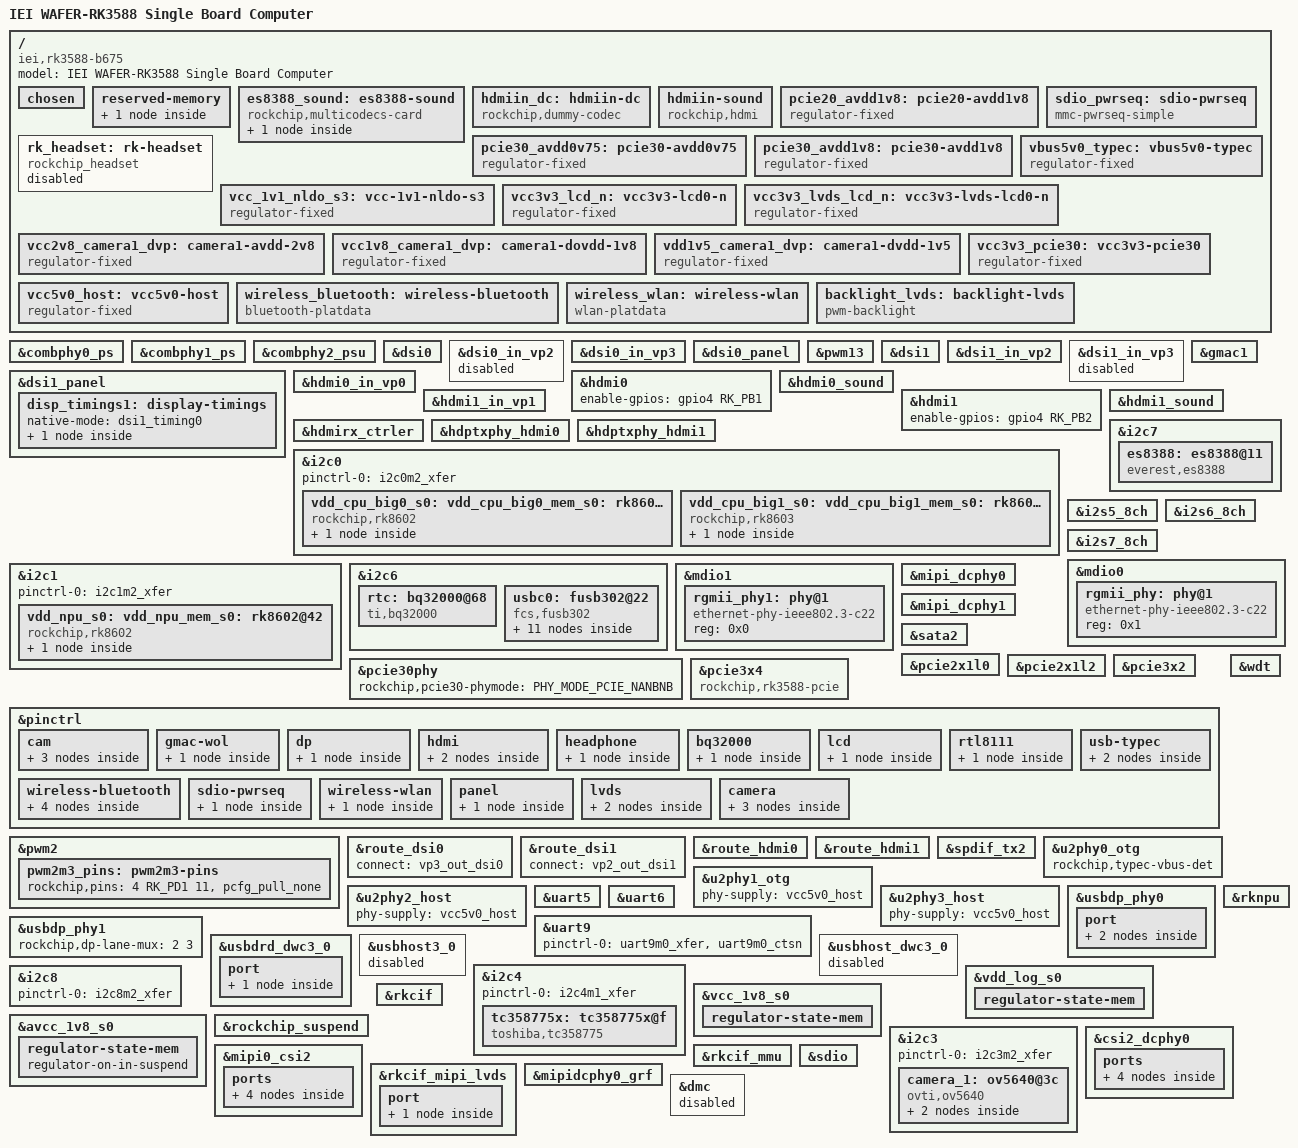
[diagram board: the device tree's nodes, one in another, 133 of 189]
// SPDX-License-Identifier: (GPL-2.0+ OR MIT)
/*
 * Copyright (c) 2024 IEI World Co., Ltd.
 * Author: LC Wang <lcwang@ieiworld.com>
 *
 */

/dts-v1/;

#include "dt-bindings/usb/pd.h"
#include "rk3588.dtsi"
#include "rk3588-evb.dtsi"
#include "rk3588-rk806-single.dtsi"
#include "rk3588-android.dtsi"

/ {

	model = "IEI WAFER-RK3588 Single Board Computer";
	compatible = "iei,rk3588-b675", "rockchip,rk3588";

	chosen: chosen {
		bootargs = "earlycon=uart8250,mmio32,0xfeb50000 console=ttyFIQ0 irqchip.gicv3_pseudo_nmi=0 rcupdate.rcu_expedited=1 rcu_nocbs=all quiet";
	};

	/* If hdmirx node is disabled, delete the reserved-memory node here. */
	reserved-memory {
		#address-cells = <2>;
		#size-cells = <2>;
		ranges;

		/* Reserve 128MB memory for hdmirx-controller@fdee0000 */
		cma {
			compatible = "shared-dma-pool";
			reusable;
			reg = <0x0 (256 * 0x100000) 0x0 (128 * 0x100000)>;
			linux,cma-default;
		};
	};

	es8388_sound: es8388-sound {
		status = "okay";
		compatible = "rockchip,multicodecs-card";
		rockchip,card-name = "rockchip-es8388";
		hp-det-gpio = <&gpio1 RK_PC4 GPIO_ACTIVE_LOW>;
		io-channels = <&saradc 3>;
		io-channel-names = "adc-detect";
		keyup-threshold-microvolt = <1800000>;
		poll-interval = <100>;
		rockchip,format = "i2s";
		rockchip,mclk-fs = <256>;
		rockchip,cpu = <&i2s0_8ch>;
		rockchip,codec = <&es8388>;
		rockchip,audio-routing =
			"Headphone", "LOUT1",
			"Headphone", "ROUT1",
			"Speaker", "LOUT2",
			"Speaker", "ROUT2",
			"Headphone", "Headphone Power",
			"Headphone", "Headphone Power",
			"Speaker", "Speaker Power",
			"Speaker", "Speaker Power",
			"LINPUT1", "Main Mic",
			"LINPUT2", "Main Mic",
			"RINPUT1", "Headset Mic",
			"RINPUT2", "Headset Mic";
		pinctrl-names = "default";
		pinctrl-0 = <&hp_det>;
		play-pause-key {
			label = "playpause";
			linux,code = <KEY_PLAYPAUSE>;
			press-threshold-microvolt = <2000>;
		};
	};

	hdmiin_dc: hdmiin-dc {
		compatible = "rockchip,dummy-codec";
		#sound-dai-cells = <0>;
		status = "okay";
	};

	hdmiin-sound {
		compatible = "rockchip,hdmi";
		rockchip,mclk-fs = <128>;
		rockchip,format = "i2s";
		rockchip,bitclock-master = <&hdmirx_ctrler>;
		rockchip,frame-master = <&hdmirx_ctrler>;
		rockchip,card-name = "rockchip,hdmiin";
		rockchip,cpu = <&i2s7_8ch>;
		rockchip,codec = <&hdmirx_ctrler 0>;
		rockchip,jack-det;
	};

	pcie20_avdd1v8: pcie20-avdd1v8 {
		compatible = "regulator-fixed";
		regulator-name = "pcie20_avdd1v8";
		regulator-boot-on;
		regulator-always-on;
		regulator-min-microvolt = <1800000>;
		regulator-max-microvolt = <1800000>;
		vin-supply = <&avcc_1v8_s0>;
	};

	pcie30_avdd0v75: pcie30-avdd0v75 {
		compatible = "regulator-fixed";
		regulator-name = "pcie30_avdd0v75";
		regulator-boot-on;
		regulator-always-on;
		regulator-min-microvolt = <750000>;
		regulator-max-microvolt = <750000>;
		vin-supply = <&avdd_0v75_s0>;
	};

	pcie30_avdd1v8: pcie30-avdd1v8 {
		compatible = "regulator-fixed";
		regulator-name = "pcie30_avdd1v8";
		regulator-boot-on;
		regulator-always-on;
		regulator-min-microvolt = <1800000>;
		regulator-max-microvolt = <1800000>;
		vin-supply = <&avcc_1v8_s0>;
	};


	sdio_pwrseq: sdio-pwrseq {
		compatible = "mmc-pwrseq-simple";
		pinctrl-names = "default";
		pinctrl-0 = <&wifi_enable_h>;
		reset-gpios = <&gpio0 RK_PA4 GPIO_ACTIVE_LOW>;
	};

	rk_headset: rk-headset {
		status = "disabled";
		compatible = "rockchip_headset";
		headset_gpio = <&gpio1 RK_PC4 GPIO_ACTIVE_LOW>;
		pinctrl-names = "default";
		pinctrl-0 = <&hp_det>;
		io-channels = <&saradc 3>;
	};

	vbus5v0_typec: vbus5v0-typec {
		compatible = "regulator-fixed";
		regulator-name = "vbus5v0_typec";
		regulator-min-microvolt = <5000000>;
		regulator-max-microvolt = <5000000>;
		enable-active-high;
		gpio = <&gpio4 RK_PA1 GPIO_ACTIVE_HIGH>;
		vin-supply = <&vcc5v0_usb>;
		pinctrl-names = "default";
		pinctrl-0 = <&typec5v_pwren>;
	};

	vcc_1v1_nldo_s3: vcc-1v1-nldo-s3 {
		compatible = "regulator-fixed";
		regulator-name = "vcc_1v1_nldo_s3";
		regulator-always-on;
		regulator-boot-on;
		regulator-min-microvolt = <1100000>;
		regulator-max-microvolt = <1100000>;
		vin-supply = <&vcc5v0_sys>;
	};

	vcc3v3_lcd_n: vcc3v3-lcd0-n {
		compatible = "regulator-fixed";
		regulator-name = "vcc3v3_lcd0_n";
		regulator-always-on;
		regulator-boot-on;
		enable-active-high;
		gpio = <&gpio3 RK_PA6 GPIO_ACTIVE_HIGH>;
		pinctrl-names = "default";
		pinctrl-0 = <&panel_en>;
		regulator-min-microvolt = <3300000>;
		regulator-max-microvolt = <3300000>;

	};

	vcc3v3_lvds_lcd_n: vcc3v3-lvds-lcd0-n {
		compatible = "regulator-fixed";
		regulator-name = "vcc3v3_lvds_lcd0_n";
		regulator-always-on;
		regulator-boot-on;
		enable-active-high;
		gpio = <&gpio2 RK_PC1 GPIO_ACTIVE_HIGH>;
		pinctrl-names = "default";
		pinctrl-0 = <&lvds_lcd_en>;
		regulator-min-microvolt = <3300000>;
		regulator-max-microvolt = <3300000>;
	};

	vcc2v8_camera1_dvp: camera1-avdd-2v8 {
		compatible = "regulator-fixed";
		regulator-name = "camera1_avdd";
		regulator-min-microvolt = <2800000>;
		regulator-max-microvolt = <2800000>;
		regulator-always-on;
		regulator-boot-on;
		enable-active-high;
	};

	vcc1v8_camera1_dvp: camera1-dovdd-1v8 {
		compatible = "regulator-fixed";
		regulator-name = "camera1_dovdd";
		regulator-min-microvolt = <1800000>;
		regulator-max-microvolt = <1800000>;
		regulator-always-on;
		regulator-boot-on;
		enable-active-high;
	};

	vdd1v5_camera1_dvp: camera1-dvdd-1v5 {
		compatible = "regulator-fixed";
		regulator-name = "camera1_dvdd";
		regulator-min-microvolt = <1500000>;
		regulator-max-microvolt = <1500000>;
		regulator-always-on;
		regulator-boot-on;
		enable-active-high;
	};

	vcc3v3_pcie30: vcc3v3-pcie30 {
		compatible = "regulator-fixed";
		regulator-name = "vcc3v3_pcie30";
		regulator-min-microvolt = <3300000>;
		regulator-max-microvolt = <3300000>;
		enable-active-high;
		gpios = <&gpio2 RK_PC5 GPIO_ACTIVE_HIGH>;
		startup-delay-us = <5000>;
		vin-supply = <&vcc12v_dcin>;
	};

	vcc5v0_host: vcc5v0-host {
		compatible = "regulator-fixed";
		regulator-name = "vcc5v0_host";
		regulator-boot-on;
		regulator-always-on;
		regulator-min-microvolt = <5000000>;
		regulator-max-microvolt = <5000000>;
		enable-active-high;
		vin-supply = <&vcc5v0_usb>;
		pinctrl-names = "default";
	};

	wireless_bluetooth: wireless-bluetooth {
		compatible = "bluetooth-platdata";
		uart_rts_gpios = <&gpio4 RK_PC4 GPIO_ACTIVE_LOW>;
		pinctrl-names = "default", "rts_gpio";
		pinctrl-0 = <&uart9m0_rtsn>, <&bt_reset_gpio>, <&bt_wake_gpio>, <&bt_irq_gpio>;
		pinctrl-1 = <&uart9_gpios>;
		BT,reset_gpio    = <&gpio1 RK_PB2 GPIO_ACTIVE_HIGH>;
		BT,wake_gpio     = <&gpio1 RK_PB1 GPIO_ACTIVE_HIGH>;
		BT,wake_host_irq = <&gpio0 RK_PA0 GPIO_ACTIVE_HIGH>;
		status = "okay";
	};

	wireless_wlan: wireless-wlan {
		compatible = "wlan-platdata";
		wifi_chip_type = "ap6275s";
		pinctrl-names = "default";
		pinctrl-0 = <&wifi_host_wake_irq>;
		WIFI,host_wake_irq = <&gpio0 RK_PB2 GPIO_ACTIVE_HIGH>;
		status = "okay";
	};

	backlight_lvds: backlight-lvds {
		compatible = "pwm-backlight";
		brightness-levels = <
			0   1   2   3   4   5   6   7
			8   9  10  11  12  13  14  15
			16  17  18  19  20  21  22  23
			24  25  26  27  28  29  30  31
			32  33  34  35  36  37  38  39
			40  41  42  43  44  45  46  47
			48  49  50  51  52  53  54  55
			56  57  58  59  60  61  62  63
			64  65  66  67  68  69  70  71
			72  73  74  75  76  77  78  79
			80  81  82  83  84  85  86  87
			88  89  90  91  92  93  94  95
			96  97  98  99 100 101 102 103
			104 105 106 107 108 109 110 111
			112 113 114 115 116 117 118 119
			120 121 122 123 124 125 126 127
			128 129 130 131 132 133 134 135
			136 137 138 139 140 141 142 143
			144 145 146 147 148 149 150 151
			152 153 154 155 156 157 158 159
			160 161 162 163 164 165 166 167
			168 169 170 171 172 173 174 175
			176 177 178 179 180 181 182 183
			184 185 186 187 188 189 190 191
			192 193 194 195 196 197 198 199
			200 201 202 203 204 205 206 207
			208 209 210 211 212 213 214 215
			216 217 218 219 220 221 222 223
			224 225 226 227 228 229 230 231
			232 233 234 235 236 237 238 239
			240 241 242 243 244 245 246 247
			248 249 250 251 252 253 254 255
		>;
		default-brightness-level = <200>;
		pwms = <&pwm2 0 25000 0>;
		enable-gpios = <&gpio4 RK_PD1 GPIO_ACTIVE_HIGH>;
	};
};

&combphy0_ps {
	status = "okay";
};

&combphy1_ps {
	status = "okay";
};

&combphy2_psu {
	status = "okay";
};

/*
 * mipi_dcphy0 needs to be enabled
 * when dsi0 is enabled
 */
&dsi0 {
	status = "okay";
};

&dsi0_in_vp2 {
	status = "disabled";
};

&dsi0_in_vp3 {
	status = "okay";
};

&dsi0_panel {
};

&pwm13 {
	status = "okay";
};

/*
 * mipi_dcphy1 needs to be enabled
 * when dsi1 is enabled
 */
&dsi1 {
	status = "okay";
};

&dsi1_in_vp2 {
	status = "okay";
};

&dsi1_in_vp3 {
	status = "disabled";
};

// TC358774
&dsi1_panel {
	power-supply = <&vcc3v3_lvds_lcd_n>;
	reset-gpios = <&gpio4 RK_PC2 GPIO_ACTIVE_LOW>;
	enable-delay-ms = <20>;
	prepare-delay-ms = <120>;
	unprepare-delay-ms = <120>;
	disable-delay-ms = <20>;
	/delete-property/ reset-delay-ms;
	pinctrl-names = "default";
	pinctrl-0 = <&lvds_lcd_rst>;
	backlight = <&backlight_lvds>;
	no-panel-reinit;

	panel-init-sequence = [
		// TC358774/75XBG DSI Basic Parameters.  Following 10 setting should be pefromed in LP mode
		29 00 06 3C 01 0B 00 08 00
		29 00 06 14 01 07 00 00 00
		29 00 06 64 01 0C 00 00 00
		29 00 06 68 01 0C 00 00 00
		29 00 06 6C 01 0C 00 00 00
		29 00 06 70 01 0C 00 00 00
		29 00 06 34 01 1F 00 00 00
		29 00 06 10 02 1F 00 00 00
		29 00 06 04 01 01 00 00 00
		29 00 06 04 02 01 00 00 00

		// TC358774/75XBG Timing and mode setting
		29 00 06 50 04 20 01 F0 03
		29 00 06 54 04 32 00 B4 00
		29 00 06 58 04 80 07 48 00
		29 00 06 5C 04 0C 00 18 00
		29 00 06 60 04 B0 04 18 00
		29 00 06 64 04 01 00 00 00
		29 01 06 A0 04 06 80 44 00
		29 00 06 A0 04 06 80 04 00
		29 00 06 04 05 04 00 00 00

		// TC358774/75XBG LVDS Color mapping setting
		29 00 06 80 04 00 01 02 03
		29 00 06 84 04 04 07 05 08
		29 00 06 88 04 09 0A 0E 0F
		29 00 06 8C 04 0B 0C 0D 10
		29 00 06 90 04 16 17 11 12
		29 00 06 94 04 13 14 15 1B
		29 00 06 98 04 18 19 1A 06

		// TC358774/75XBG LVDS enable
		29 00 06 9C 04 33 04 00 00
	];

	panel-exit-sequence = [
		05 05 01 28
		05 78 01 10
	];

	disp_timings1: display-timings {
		native-mode = <&dsi1_timing0>;
		dsi1_timing0: timing0 {
			clock-frequency = <168000000>;
			hactive = <1920>;
			hsync-len = <50>;
			hback-porch = <180>;
			hfront-porch = <72>;
			vactive = <1200>;
			vsync-len = <12>;
			vback-porch = <24>;
			vfront-porch = <24>;
			hsync-active = <0>;
			vsync-active = <0>;
			de-active = <0>;
			pixelclk-active = <0>;
		};
	};
};

&gmac1 {
	/* Use rgmii-rxid mode to disable rx delay inside Soc */
	phy-mode = "rgmii-rxid";
	clock_in_out = "output";
	wolirq-gpio = <&gpio4 RK_PC6 GPIO_ACTIVE_LOW>;
	snps,reset-gpio = <&gpio3 RK_PB7 GPIO_ACTIVE_LOW>;
	snps,reset-active-low;
	/* Reset time is 20ms, 100ms for rtl8211f */
	snps,reset-delays-us = <0 50000 100000>;

	pinctrl-names = "default";
	pinctrl-0 = <&gmac1_miim
		     &gmac1_tx_bus2
		     &gmac1_rx_bus2
		     &gmac1_rgmii_clk
		     &gmac1_rgmii_bus
		     &gmac1_pmeb_gpios>;

	tx_delay = <0x43>;
	/* rx_delay = <0x3f>; */

	phy-handle = <&rgmii_phy1>;
	status = "okay";
};

&hdmi0 {
	enable-gpios = <&gpio4 RK_PB1 GPIO_ACTIVE_HIGH>;
	status = "okay";
};

&hdmi0_in_vp0 {
	status = "okay";
};

&hdmi0_sound {
	status = "okay";
};

&hdmi1 {
	enable-gpios = <&gpio4 RK_PB2 GPIO_ACTIVE_HIGH>;
	status = "okay";
};

&hdmi1_in_vp1 {
	status = "okay";
};

&hdmi1_sound {
	status = "okay";
};

/* Should work with at least 128MB cma reserved above. */
&hdmirx_ctrler {
	status = "okay";

	#sound-dai-cells = <1>;
	/* Effective level used to trigger HPD: 0-low, 1-high */
	hpd-trigger-level = <1>;
	hdmirx-det-gpios = <&gpio1 RK_PD5 GPIO_ACTIVE_LOW>;
	pinctrl-names = "default";
	pinctrl-0 = <&hdmim1_rx &hdmirx_det>;
};

&hdptxphy_hdmi0 {
	status = "okay";
};

&hdptxphy_hdmi1 {
	status = "okay";
};

&i2c0 {
	status = "okay";
	pinctrl-names = "default";
	pinctrl-0 = <&i2c0m2_xfer>;

	vdd_cpu_big0_s0: vdd_cpu_big0_mem_s0: rk8602@42 {
		compatible = "rockchip,rk8602";
		reg = <0x42>;
		vin-supply = <&vcc5v0_sys>;
		regulator-compatible = "rk860x-reg";
		regulator-name = "vdd_cpu_big0_s0";
		regulator-min-microvolt = <550000>;
		regulator-max-microvolt = <1050000>;
		regulator-ramp-delay = <2300>;
		rockchip,suspend-voltage-selector = <1>;
		regulator-boot-on;
		regulator-always-on;
		regulator-state-mem {
			regulator-off-in-suspend;
		};
	};

	vdd_cpu_big1_s0: vdd_cpu_big1_mem_s0: rk8603@43 {
		compatible = "rockchip,rk8603";
		reg = <0x43>;
		vin-supply = <&vcc5v0_sys>;
		regulator-compatible = "rk860x-reg";
		regulator-name = "vdd_cpu_big1_s0";
		regulator-min-microvolt = <550000>;
		regulator-max-microvolt = <1050000>;
		regulator-ramp-delay = <2300>;
		rockchip,suspend-voltage-selector = <1>;
		regulator-boot-on;
		regulator-always-on;
		regulator-state-mem {
			regulator-off-in-suspend;
		};
	};
};

&i2c1 {
	pinctrl-0 = <&i2c1m2_xfer>;
	status = "okay";

	vdd_npu_s0: vdd_npu_mem_s0: rk8602@42 {
		compatible = "rockchip,rk8602";
		reg = <0x42>;
		vin-supply = <&vcc5v0_sys>;
		regulator-compatible = "rk860x-reg";
		regulator-name = "vdd_npu_s0";
		regulator-min-microvolt = <550000>;
		regulator-max-microvolt = <950000>;
		regulator-ramp-delay = <2300>;
		rockchip,suspend-voltage-selector = <1>;
		regulator-boot-on;
		regulator-always-on;
		regulator-state-mem {
			regulator-off-in-suspend;
		};
	};

};

&i2c6 {
	status = "okay";

	rtc: bq32000@68 {
		compatible = "ti,bq32000";
		reg = <0x68>;

		pinctrl-names = "default";
		pinctrl-0 = <&bq32000_int>;
		interrupt-parent = <&gpio0>;
		interrupts = <RK_PB0 IRQ_TYPE_LEVEL_LOW>;
		wakeup-source;
	};

	usbc0: fusb302@22 {
		compatible = "fcs,fusb302";
		reg = <0x22>;
		interrupt-parent = <&gpio0>;
		interrupts = <RK_PD3 IRQ_TYPE_LEVEL_LOW>;
		pinctrl-names = "default";
		pinctrl-0 = <&usbc0_int>;
		vbus-supply = <&vbus5v0_typec>;
		status = "okay";

		ports {
			#address-cells = <1>;
			#size-cells = <0>;

			port@0 {
				reg = <0>;
				usbc0_role_sw: endpoint@0 {
					remote-endpoint = <&dwc3_0_role_switch>;
				};
			};
		};

		usb_con: connector {
			compatible = "usb-c-connector";
			label = "USB-C";
			data-role = "dual";
			power-role = "dual";
			try-power-role = "sink";
			op-sink-microwatt = <1000000>;
			sink-pdos =
				<PDO_FIXED(5000, 1000, PDO_FIXED_USB_COMM)>;
			source-pdos =
				<PDO_FIXED(5000, 3000, PDO_FIXED_USB_COMM)>;

			altmodes {
				#address-cells = <1>;
				#size-cells = <0>;

				altmode@0 {
					reg = <0>;
					svid = <0xff01>;
					vdo = <0xffffffff>;
				};
			};

			ports {
				#address-cells = <1>;
				#size-cells = <0>;

				port@0 {
					reg = <0>;
					usbc0_orien_sw: endpoint {
						remote-endpoint = <&usbdp_phy0_orientation_switch>;
					};
				};

				port@1 {
					reg = <1>;
					dp_altmode_mux: endpoint {
						remote-endpoint = <&usbdp_phy0_dp_altmode_mux>;
					};
				};
			};
		};
	};
};

&i2c7 {
	status = "okay";
	es8388: es8388@11 {
		status = "okay";
		#sound-dai-cells = <0>;
		compatible = "everest,es8388", "everest,es8323";
		reg = <0x11>;
		clocks = <&mclkout_i2s0>;
		clock-names = "mclk";
		assigned-clocks = <&mclkout_i2s0>;
		assigned-clock-rates = <12288000>;
		pinctrl-names = "default";
		pinctrl-0 = <&i2s0_mclk>;
	};
};

&i2s5_8ch {
	status = "okay";
};

&i2s6_8ch {
	status = "okay";
};

&i2s7_8ch {
	status = "okay";
};

&mdio0 {
	rgmii_phy: phy@1 {
		compatible = "ethernet-phy-ieee802.3-c22";
		reg = <0x1>;
	};
};

&mdio1 {
	rgmii_phy1: phy@1 {
		compatible = "ethernet-phy-ieee802.3-c22";
		reg = <0x0>;
	};
};

&mipi_dcphy0 {
	status = "okay";
};

&mipi_dcphy1 {
	status = "okay";
};

&sata2 {
	status = "okay";
};

&pcie2x1l0 {
	phys = <&combphy1_ps PHY_TYPE_PCIE>;
	reset-gpios = <&gpio1 RK_PB4 GPIO_ACTIVE_HIGH>;
	vpcie3v3-supply = <&vcc3v3_pcie30>;
	status = "okay";
};

&pcie2x1l2 {
        phys = <&combphy0_ps PHY_TYPE_PCIE>;
	reset-gpios = <&gpio3 RK_PD1 GPIO_ACTIVE_HIGH>;
	vpcie3v3-supply = <&vcc3v3_pcie30>;
        status = "okay";
};

&pcie30phy {
	rockchip,pcie30-phymode = <PHY_MODE_PCIE_NANBNB>;
	status = "okay";
};

&pcie3x2 {
	reset-gpios = <&gpio4 RK_PB0 GPIO_ACTIVE_HIGH>;
	vpcie3v3-supply = <&vcc3v3_pcie30>;
	status = "okay";
};

&pcie3x4 {
	compatible = "rockchip,rk3588-pcie", "snps,dw-pcie";
	num-lanes = <2>;
	reset-gpios = <&gpio4 RK_PB6 GPIO_ACTIVE_HIGH>;
	vpcie3v3-supply = <&vcc3v3_pcie30>;
	/delete-property/ memory-region;
	/delete-property/ busno;
	status = "okay";
};

&pinctrl {
	cam {
		mipicsi0_pwr: mipicsi0-pwr {
			rockchip,pins =
				/* camera power en */
				<1 RK_PB1 RK_FUNC_GPIO &pcfg_pull_none>;
		};
		mipicsi1_pwr: mipicsi1-pwr {
			rockchip,pins =
				/* camera power en */
				<1 RK_PB2 RK_FUNC_GPIO &pcfg_pull_none>;
		};
		mipidcphy0_pwr: mipidcphy0-pwr {
			rockchip,pins =
				/* camera power en */
				<2 RK_PC4 RK_FUNC_GPIO &pcfg_pull_none>;
		};
	};

	gmac-wol {
		gmac1_pmeb_gpios:  gmac1-pmeb-gpios {
			rockchip,pins = <4 RK_PC6 RK_FUNC_GPIO &pcfg_pull_none>;
		};
	};

	dp {
		dp1_hpd: dp1-hpd {
			rockchip,pins = <1 RK_PB5 RK_FUNC_GPIO &pcfg_pull_none>;
		};
	};

	hdmi {
		hdmirx_det: hdmirx-det {
			rockchip,pins = <1 RK_PD5 RK_FUNC_GPIO &pcfg_pull_up>;
		};

        hdmim1_rx: hdmim1-rx {
            rockchip,pins =
                /* hdmim1_rx_cec */
                <3 RK_PD1 5 &pcfg_pull_none>,
                /* hdmim1_rx_scl */
                <3 RK_PD2 5 &pcfg_pull_none_smt>,
                /* hdmim1_rx_sda */
                <3 RK_PD3 5 &pcfg_pull_none_smt>,
                /* hdmim1_rx_hpdin */
                <3 RK_PD4 5 &pcfg_pull_none>;
        };
	};

	headphone {
		hp_det: hp-det {
			rockchip,pins = <1 RK_PC4 RK_FUNC_GPIO &pcfg_pull_none>;
		};
	};

	bq32000 {
		bq32000_int: bq32000-int {
			rockchip,pins = <0 RK_PB0 RK_FUNC_GPIO &pcfg_pull_up>;
		};
	};

	lcd {
		lcd_rst_gpio: lcd-rst-gpio {
			rockchip,pins = <2 RK_PB4 RK_FUNC_GPIO &pcfg_pull_none>;
		};
	};

	rtl8111 {
		rtl8111_isolate: rtl8111-isolate {
			rockchip,pins = <1 RK_PA4 RK_FUNC_GPIO &pcfg_pull_up>;
		};
	};

	usb-typec {
		usbc0_int: usbc0-int {
			rockchip,pins = <0 RK_PD3 RK_FUNC_GPIO &pcfg_pull_up>;
		};

		typec5v_pwren: typec5v-pwren {
			rockchip,pins = <4 RK_PA1 RK_FUNC_GPIO &pcfg_pull_none>;
		};
	};

	wireless-bluetooth {
		uart9_gpios: uart9-gpios {
			rockchip,pins = <4 RK_PC4 RK_FUNC_GPIO &pcfg_pull_none>;
		};

		bt_reset_gpio: bt-reset-gpio {
			rockchip,pins = <1 RK_PB2 RK_FUNC_GPIO &pcfg_pull_none>;
		};

		bt_wake_gpio: bt-wake-gpio {
			rockchip,pins = <1 RK_PB1 RK_FUNC_GPIO &pcfg_pull_none>;
		};

		bt_irq_gpio: bt-irq-gpio {
			rockchip,pins = <0 RK_PA0 RK_FUNC_GPIO &pcfg_pull_down>;
		};
	};

	sdio-pwrseq {
		wifi_enable_h: wifi-enable-h {
			rockchip,pins = <0 RK_PA4 RK_FUNC_GPIO &pcfg_pull_none>;
		};
	};

	wireless-wlan {
		wifi_host_wake_irq: wifi-host-wake-irq {
			rockchip,pins = <0 RK_PB2 RK_FUNC_GPIO &pcfg_pull_down>;
		};
	};

	panel {
		panel_en: panel-en {
			rockchip,pins = <3 RK_PA6 RK_FUNC_GPIO &pcfg_pull_none>;
		};
	};

	lvds {
		lvds_lcd_en: lvds-lcd-en {
			rockchip,pins = <2 RK_PC1 RK_FUNC_GPIO &pcfg_pull_down>;
		};

		lvds_lcd_rst: lvds-lcd-rst {
			rockchip,pins = <4 RK_PC2 RK_FUNC_GPIO &pcfg_pull_down>;
		};
	};

	camera {
		camera_en: camera-en {
			rockchip,pins = <1 RK_PD2 RK_FUNC_GPIO &pcfg_pull_up>;
		};

		camera_pwdn: camera-pwdn {
			rockchip,pins = <1 RK_PA4 RK_FUNC_GPIO &pcfg_pull_up>;
		};

		camera_rst: camera-rst {
			rockchip,pins = <1 RK_PA7 RK_FUNC_GPIO &pcfg_pull_down>;
		};
	};
};

&pwm2 {
	status = "okay";

	// lvds bkl enable pinmux
	/omit-if-no-ref/
        pwm2m3_pins: pwm2m3-pins {
		rockchip,pins =
			/* pwm2_m3 */
			<4 RK_PD1 11 &pcfg_pull_none>;
	};
};

&route_dsi0 {
	status = "okay";
	connect = <&vp3_out_dsi0>;
};

&route_dsi1 {
	status = "okay";
	connect = <&vp2_out_dsi1>;
};

&route_hdmi0 {
	status = "okay";
};

&route_hdmi1 {
	status = "okay";
};

&spdif_tx2 {
	status = "okay";
};

&u2phy0_otg {
	rockchip,typec-vbus-det;
};

&u2phy1_otg {
	phy-supply = <&vcc5v0_host>;
};

&u2phy2_host {
	phy-supply = <&vcc5v0_host>;
};

&u2phy3_host {
	phy-supply = <&vcc5v0_host>;
};

&uart5 {
	status = "okay";
	pinctrl-0 = <&uart5m0_xfer &uart5m0_ctsn &uart5m0_rtsn>;
};

&uart6 {
	status = "okay";
	pinctrl-0 = <&uart6m1_xfer &uart6m1_ctsn &uart6m1_rtsn>;
};

&uart9 {
	status = "okay";
	pinctrl-names = "default";
	pinctrl-0 = <&uart9m0_xfer &uart9m0_ctsn>;
};

&usbdp_phy0 {
	orientation-switch;
	svid = <0xff01>;
	sbu1-dc-gpios = <&gpio4 RK_PA6 GPIO_ACTIVE_HIGH>;
	sbu2-dc-gpios = <&gpio4 RK_PA7 GPIO_ACTIVE_HIGH>;

	port {
		#address-cells = <1>;
		#size-cells = <0>;
		usbdp_phy0_orientation_switch: endpoint@0 {
			reg = <0>;
			remote-endpoint = <&usbc0_orien_sw>;
		};

		usbdp_phy0_dp_altmode_mux: endpoint@1 {
			reg = <1>;
			remote-endpoint = <&dp_altmode_mux>;
		};
	};
};

&usbdp_phy1 {
	rockchip,dp-lane-mux = <2 3>;
};

&usbdrd_dwc3_0 {
	dr_mode = "otg";
	usb-role-switch;
	port {
		#address-cells = <1>;
		#size-cells = <0>;
		dwc3_0_role_switch: endpoint@0 {
			reg = <0>;
			remote-endpoint = <&usbc0_role_sw>;
		};
	};
};

&usbhost3_0 {
	status = "disabled";
};

&usbhost_dwc3_0 {
	status = "disabled";
};

&wdt {
    status = "okay";
};

&i2c4 {
	pinctrl-0 = <&i2c4m1_xfer>;
	status = "okay";

	tc358775x: tc358775x@f {
		compatible = "toshiba,tc358775";
		reg = <0x0f>;
		pinctrl-names = "default";
		pinctrl-0 = <&lvds_lcd_rst>;
	};
};

&i2c8 {
	pinctrl-names = "default";
	pinctrl-0 = <&i2c8m2_xfer>;
	status = "okay";

};

&vdd_log_s0 {
	regulator-state-mem {
		regulator-on-in-suspend;
		regulator-suspend-microvolt = <750000>;
	};
};

&vcc_1v8_s0 {
	regulator-state-mem {
		regulator-on-in-suspend;
		regulator-suspend-microvolt = <1800000>;
	};
};

&avcc_1v8_s0 {
		regulator-state-mem {
		regulator-on-in-suspend;
	};
};

&rockchip_suspend {
	status = "okay";
	rockchip,sleep-mode-config = <
		(0
		| RKPM_SLP_ARMOFF_DDRPD
		)
		>;
	rockchip,wakeup-config = <
		(0
		| RKPM_CPU0_WKUP_EN
		| RKPM_GPIO_WKUP_EN
		)
		>;
};

&rknpu {
	status = "okay";
};

&i2c3 {
	pinctrl-names = "default";
	pinctrl-0 = <&i2c3m2_xfer>;
	status = "okay";

	camera_1: ov5640@3c {
		compatible = "ovti,ov5640";
		reg = <0x3c>;

		clocks = <&cru CLK_MIPI_CAMARAOUT_M1>;
		clock-names = "xvclk";
		pinctrl-names = "default";
		pinctrl-0 = <&mipim0_camera1_clk>, <&camera_en>, <&camera_pwdn>, <&camera_rst>;
		avdd-supply = <&vcc2v8_camera1_dvp>;
		dovdd-supply = <&vcc1v8_camera1_dvp>;
		dvdd-supply = <&vdd1v5_camera1_dvp>;

		pwdn-gpios = <&gpio1 RK_PA4 GPIO_ACTIVE_LOW>;

		rockchip,camera-module-index = <1>;
		rockchip,camera-module-facing = "front";
		rockchip,camera-module-name = "ov5640";
		rockchip,camera-module-lens-name = "default";

		status = "okay";

		port {
			camera_1_out: endpoint {
				data-lanes = <1 2>;
				remote-endpoint = <&csidcphy0_in>;
			};
		};
	};
};

&csi2_dcphy0 {
	status = "okay";

	ports {
		#address-cells = <1>;
		#size-cells = <0>;

		port@0 {
			reg = <0>;
			#address-cells = <1>;
			#size-cells = <0>;

			csidcphy0_in: endpoint@1 {
				reg = <1>;
				remote-endpoint = <&camera_1_out>;
				data-lanes = <1 2>;
			};
		};

		port@1 {
			reg = <1>;
			#address-cells = <1>;
			#size-cells = <0>;

			csidcphy0_out: endpoint@0 {
				reg = <0>;
				remote-endpoint = <&mipi0_csi2_input>;
			};
		};
	};
};

&mipi0_csi2 {
	status = "okay";

	ports {
		#address-cells = <1>;
		#size-cells = <0>;

		port@0 {
			reg = <0>;
			#address-cells = <1>;
			#size-cells = <0>;

			mipi0_csi2_input: endpoint@1 {
				reg = <1>;
				remote-endpoint = <&csidcphy0_out>;
			};
		};

		port@1 {
			reg = <1>;
			#address-cells = <1>;
			#size-cells = <0>;

			mipi0_csi2_output: endpoint@0 {
				reg = <0>;
				remote-endpoint = <&cif_mipi_in0>;
				data-lanes = <1 2>;
			};
		};
	};
};

&rkcif {
	status = "okay";
};

&rkcif_mmu {
	status = "okay";
};

&rkcif_mipi_lvds {
	status = "okay";

	port {
		cif_mipi_in0: endpoint {
			remote-endpoint = <&mipi0_csi2_output>;
			data-lanes = <1 2>;
		};
	};
};

&mipidcphy0_grf {
	status = "okay";
};

&sdio {
	max-frequency = <150000000>;
	supports-sdio;
	bus-width = <4>;
	disable-wp;
	cap-sd-highspeed;
	cap-sdio-irq;
	keep-power-in-suspend;
	mmc-pwrseq = <&sdio_pwrseq>;
	non-removable;
	num-slots = <1>;
	pinctrl-names = "default";
	pinctrl-0 = <&sdiom0_pins>;
	sd-uhs-sdr104;
	status = "okay";
};

&dmc {
	status = "disabled";
};
